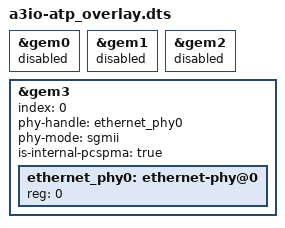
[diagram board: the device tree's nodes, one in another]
/dts-v1/;
/plugin/;

#include <dt-bindings/input/input.h>
#include <dt-bindings/gpio/gpio.h>
#include <dt-bindings/pinctrl/pinctrl-zynqmp.h>
#include <dt-bindings/phy/phy.h>

&gem0 {
    status = "disabled";
};

&gem1 {
    status = "disabled";
};

&gem2 {
    status = "disabled";
};

&gem3 {
    status = "okay";
    index = <0>; /* Use eth0 */
    phy-handle = <&ethernet_phy0>;
    phy-mode = "sgmii";
    is-internal-pcspma = "true";
    ethernet_phy0: ethernet-phy@0 {
        reg = <0>;
    };
};
